# CEC1702 device description
Architecture: CORTEX-M4; Family: CEC1702; Series: CEC1702Q
Registers are 32-bit, read-write, reset 0x0 unless marked. A register's access mark holds for its fields unless they carry their own. Offsets are from the block's base; [hi:lo] are bit positions.

## GP_SPI — The General Purpose Serial Peripheral Interface (GP-SPI) may be used to communicate with various peripheral devices, e.g., EEPROMS, DACs, ADCs, that use a standard Serial Peripheral Interface.
Instances: GP_SPI0 0x40009400
0x00 ENABLE reset 0xF — [0:0] 1=Enabled. The device is fully operational. 0=Disabled. Clocks are gated to conserve power and the SPDOUT and SPI_CLK signals are set to their inactive state
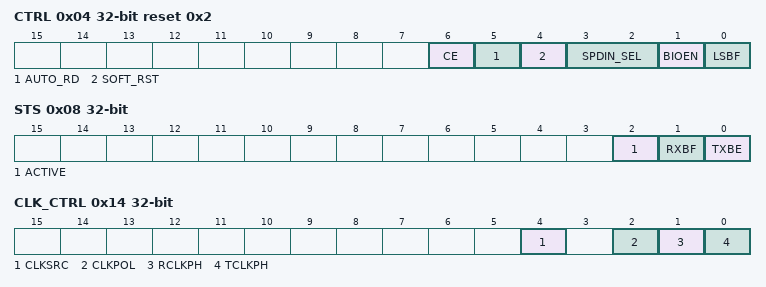
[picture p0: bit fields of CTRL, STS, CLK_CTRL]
0x04 CTRL reset 0x2 — SPI Control
  [6] CE — SPI Chip Select Enable. 1= SPI_CS# output signal is asserted, i.e., driven to logic '0' 0= SPI_CS# output signal is deasserted, i.e., driven to logic '1'
  [5] AUTO_RD — Auto Read Enable. 1=A read of the SPI RX_DATA Register will clear both the RXBF status bit and the TXBE status bit. 0=A read of the SPI RX_DATA Register will clear the RXBF status bit. The TXBE status bit will not be modified
  [4] SOFT_RST — Soft Reset is a self-clearing bit. Writing zero to this bit has no effect. Writing a one to this bit resets the entire SPI Interface, including all counters and registers back to their initial state.
  [3:2] SPDIN_SEL — [3:2] 1xb=SPDIN1 and SPDIN2. Select this option for Dual Mode [3:2] 01b=SPDIN2 only. Select this option for Half Duplex [3:2] 00b=SPDIN1 only. Select this option for Full Duplex
  [1] BIOEN — Bidirectional Output Enable control. 1=The SPDOUT_Direction signal configures the SPDOUT signal as an output. 0=The SPDOUT_Direction signal configures the SPDOUT signal as an input.
  [0] LSBF — Least Significant Bit First. 1= The data is transferred in LSB-first order. 0= The data is transferred in MSB-first order. (default)
0x08 STS ro — SPI Status
  [2] ACTIVE — ACTIVE status
  [1] RXBF — 1=RX_Data buffer is full, 0=RX_Data buffer is not full
  [0] TXBE — 1=TX_Data buffer is empty, 0=TX_Data buffer is not empty
0x0C TX_DAT — [7:0] A write to this register when the. Tx_Data buffer is empty (TXBE in the SPI Status Register is '1') initiates a SPI transaction.
0x10 RX_DAT — [7:0] This register is used to read the value returned by the external SPI device.
0x14 CLK_CTRL — SPI Clock Control. This register should not be changed during an active SPI transaction.
  [4] CLKSRC — 1=2MHz, 0=48 MHz Ring Oscillator
  [2] CLKPOL — 1=The SPI_CLK signal is high when the interface is idle and the first clock edge is a falling edge. 0=The SPI_CLK is low when the interface is idle and the first clock edge is a rising edge
  [1] RCLKPH — 1=Valid data on SPDIN signal is expected after the first SPI_CLK edge. This data is sampled on the second and following even SPI_CLK edges (i.e., sample data on falling edge) 0=Valid data is expected on the SPDIN signal on the first SPI_CLK edge. This data is sampled on the first and following odd SPI_-CLK edges (i.e., sample data on rising edge)
  [0] TCLKPH — 1=Valid data is clocked out on the first SPI_CLK edge on SPDOUT signal. The slave device should sample this data on the second and following even SPI_CLK edges (i.e., sample data on falling edge) 0=Valid data is clocked out on the SPDOUT signal prior to the first SPI_CLK edge. The slave device should sample this data on the first and following odd SPI_CLK edges (i.e., sample data on rising edge)
0x18 CLK_GEN reset 0x2 — [5:0] PRELOAD SPI Clock Generator Preload value.
  [5:0] PRLD — SPI Clock Generator Preload Value

## TFDP — The TFDP serially transmits Embedded Controller (EC)-originated diagnostic vectors to an external debug trace system.
Instances: TFDP 0x40008C00
0x00 MSDATA 8-bit — Debug data to be shifted out on the TFDP Debug port. While data is being shifted out, the Host Interface will 'hold-off' additional writes to the data register until the transfer is complete.
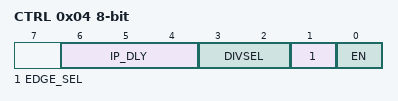
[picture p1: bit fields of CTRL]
0x04 CTRL 8-bit — Debug Control Register
  [6:4] IP_DLY — Inter-packet Delay. The delay is in terms of TFDP Debug output clocks.
  [3:2] DIVSEL — Clock Divider Select.
  [1] EDGE_SEL — 1= Data is shifted out on the falling edge of the debug clock, 0= Data is shifted out on the rising edge of the debug clock (Default)
  [0] EN — Enable. 1=Clock enabled, 0=Clock is disabled (Default)
